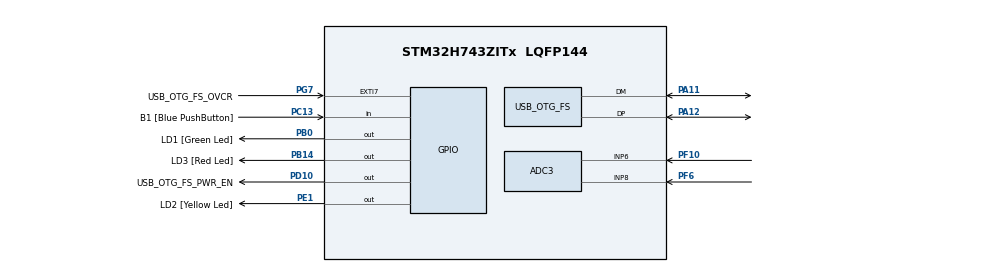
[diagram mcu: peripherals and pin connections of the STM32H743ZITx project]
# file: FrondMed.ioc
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ADC3.Channel-1\#ChannelRegularConversion=ADC_CHANNEL_6
ADC3.Channel-2\#ChannelRegularConversion=ADC_CHANNEL_8
ADC3.ExternalTrigConv=ADC_EXTERNALTRIG_T2_TRGO
ADC3.NbrOfConversion=2
ADC3.NbrOfConversionFlag=1
ADC3.OffsetNumber-1\#ChannelRegularConversion=ADC_OFFSET_NONE
ADC3.OffsetNumber-2\#ChannelRegularConversion=ADC_OFFSET_NONE
ADC3.OffsetSignedSaturation-1\#ChannelRegularConversion=DISABLE
ADC3.OffsetSignedSaturation-2\#ChannelRegularConversion=DISABLE
ADC3.Overrun=ADC_OVR_DATA_OVERWRITTEN
ADC3.Rank-1\#ChannelRegularConversion=1
ADC3.Rank-2\#ChannelRegularConversion=2
ADC3.SamplingTime-1\#ChannelRegularConversion=ADC_SAMPLETIME_1CYCLE_5
ADC3.SamplingTime-2\#ChannelRegularConversion=ADC_SAMPLETIME_1CYCLE_5
CORTEX_M7.CPU_DCache=Enabled
CORTEX_M7.CPU_ICache=Enabled
Dma.ADC3.0.Direction=DMA_PERIPH_TO_MEMORY
Dma.ADC3.0.EventEnable=DISABLE
Dma.ADC3.0.FIFOMode=DMA_FIFOMODE_DISABLE
Dma.ADC3.0.Instance=DMA1_Stream0
Dma.ADC3.0.MemDataAlignment=DMA_MDATAALIGN_HALFWORD
Dma.ADC3.0.MemInc=DMA_MINC_ENABLE
Dma.ADC3.0.Mode=DMA_CIRCULAR
Dma.ADC3.0.PeriphDataAlignment=DMA_PDATAALIGN_HALFWORD
Dma.ADC3.0.PeriphInc=DMA_PINC_DISABLE
Dma.ADC3.0.Polarity=HAL_DMAMUX_REQ_GEN_RISING
Dma.ADC3.0.Priority=DMA_PRIORITY_LOW
Dma.ADC3.0.RequestNumber=1
Dma.ADC3.0.SignalID=NONE
Dma.ADC3.0.SyncEnable=DISABLE
Dma.ADC3.0.SyncPolarity=HAL_DMAMUX_SYNC_NO_EVENT
Dma.ADC3.0.SyncRequestNumber=1
Dma.ADC3.0.SyncSignalID=NONE
Dma.Request0=ADC3
FREERTOS.INCLUDE_uxTaskPriorityGet=1
FREERTOS.INCLUDE_vTaskDelayUntil=1
FREERTOS.INCLUDE_vTaskDelete=1
FREERTOS.Tasks01=defaultTask,24,256,StartDefaultTask,Default,NULL,Dynamic,NULL,NULL
FREERTOS.configTOTAL_HEAP_SIZE=32768
Mcu.Family=STM32H7
Mcu.Name=STM32H743ZITx
Mcu.Package=LQFP144
NVIC.ADC3_IRQn=true\:5\:0\:false\:false\:true\:true\:true\:true\:true
NVIC.DMA1_Stream0_IRQn=true\:5\:0\:false\:false\:true\:true\:false\:true\:true
NVIC.OTG_FS_IRQn=true\:5\:0\:false\:false\:true\:true\:true\:true\:true
NVIC.PriorityGroup=NVIC_PRIORITYGROUP_4
NVIC.TIM6_DAC_IRQn=true\:15\:0\:false\:false\:true\:false\:false\:true\:true
NVIC.TimeBase=TIM6_DAC_IRQn
NVIC.TimeBaseIP=TIM6
PA1.Signal=ETH_REF_CLK
PA11.Mode=Device_Only
PA11.Signal=USB_OTG_FS_DM
PA12.Mode=Device_Only
PA12.Signal=USB_OTG_FS_DP
PA2.Signal=ETH_MDIO
PA7.Signal=ETH_CRS_DV
PA8.Signal=USB_OTG_FS_SOF
PA9.Signal=USB_OTG_FS_VBUS
PB0.GPIO_Label=LD1 [Green Led]
PB0.Signal=GPIO_Output
PB13.Signal=ETH_TXD1
PB14.GPIO_Label=LD3 [Red Led]
PB14.Signal=GPIO_Output
PC1.Signal=ETH_MDC
PC13.GPIO_Label=B1 [Blue PushButton]
PC13.Signal=GPIO_Input
PC14-OSC32_IN\ (OSC32_IN).Mode=LSE-External-Clock-Source
PC14-OSC32_IN\ (OSC32_IN).Signal=RCC_OSC32_IN
PC15-OSC32_OUT\ (OSC32_OUT).Signal=RCC_OSC32_OUT
PC4.Signal=ETH_RXD0
PC5.Signal=ETH_RXD1
PD10.GPIO_Label=USB_OTG_FS_PWR_EN
PD10.Signal=GPIO_Output
PD8.GPIO_Label=STLINK_RX
PD8.Signal=USART3_TX
PD9.GPIO_Label=STLINK_TX
PD9.Signal=USART3_RX
PE1.GPIO_Label=LD2 [Yellow Led]
PE1.Signal=GPIO_Output
PF10.Mode=IN6-Single-Ended
PF10.Signal=ADC3_INP6
PF6.Mode=IN8-Single-Ended
PF6.Signal=ADC3_INP8
PG11.Signal=ETH_TX_EN
PG13.Signal=ETH_TXD0
PG7.GPIO_Label=USB_OTG_FS_OVCR
PG7.Signal=GPXTI7
PH0-OSC_IN\ (PH0).Mode=HSE-External-Clock-Source
PH0-OSC_IN\ (PH0).Signal=RCC_OSC_IN
PH1-OSC_OUT\ (PH1).Signal=RCC_OSC_OUT
ProjectManager.HeapSize=0x200
ProjectManager.StackSize=0x400
ProjectManager.TargetToolchain=MDK-ARM V5.32
RCC.ADCFreq_Value=150000000
RCC.APB1Freq_Value=120000000
RCC.APB2Freq_Value=120000000
RCC.APB3Freq_Value=120000000
RCC.APB4Freq_Value=120000000
RCC.CortexFreq_Value=480000000
RCC.D1PPRE=RCC_APB3_DIV2
RCC.D2PPRE1=RCC_APB1_DIV2
RCC.D2PPRE2=RCC_APB2_DIV2
RCC.D3PPRE=RCC_APB4_DIV2
RCC.DIVM1=1
RCC.DIVM2=1
RCC.DIVN1=120
RCC.DIVN2=18
RCC.DIVP2=1
RCC.DIVQ1=15
RCC.HCLKFreq_Value=240000000
RCC.HPRE=RCC_HCLK_DIV2
RCC.HSE_VALUE=8000000
RCC.PLL2FRACN=6144
RCC.PLL3FRACN=0
RCC.PLLFRACN=0
RCC.PLLSourceVirtual=RCC_PLLSOURCE_HSE
RCC.PWR_Regulator_Voltage_Scale=PWR_REGULATOR_VOLTAGE_SCALE0
RCC.SYSCLKFreq_VALUE=480000000
RCC.SYSCLKSource=RCC_SYSCLKSOURCE_PLLCLK
RCC.USBCLockSelection=RCC_USBCLKSOURCE_HSI48
RCC.USBFreq_Value=48000000
TIM2.Period=399
TIM2.Prescaler=23
TIM2.TIM_MasterOutputTrigger=TIM_TRGO_UPDATE
USB_DEVICE.CLASS_NAME_FS=CDC
USB_DEVICE.VirtualMode-CDC_FS=Cdc
USB_DEVICE.VirtualModeFS=Cdc_FS
USB_OTG_FS.VirtualMode=Device_Only
USB_OTG_FS.dma_enable=ENABLE
VP_FREERTOS_VS_CMSIS_V2.Mode=CMSIS_V2
VP_SYS_VS_tim6.Mode=TIM6
VP_TIM2_VS_ClockSourceINT.Mode=Internal
VP_USB_DEVICE_VS_USB_DEVICE_CDC_FS.Mode=CDC_FS
board=NUCLEO-H743ZI2

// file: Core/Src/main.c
/* USER CODE BEGIN Header */
/**
  ******************************************************************************
  * @file           : main.c
  * @brief          : Main program body
  ******************************************************************************
  * @attention
  *
  * Copyright (c) 2022 STMicroelectronics.
  * All rights reserved.
  *
  * This software is licensed under terms that can be found in the LICENSE file
  * in the root directory of this software component.
  * If no LICENSE file comes with this software, it is provided AS-IS.
  *
  ******************************************************************************
  */
/* USER CODE END Header */
#include "main.h"
#include "cmsis_os.h"
#include "usb_device.h"

/* USER CODE BEGIN PM */
extern  void mainThread(void* arg);

/* USER CODE END PM */

ADC_HandleTypeDef hadc3;
DMA_HandleTypeDef hdma_adc3;

TIM_HandleTypeDef htim2;

/* Definitions for defaultTask */
osThreadId_t defaultTaskHandle;
const osThreadAttr_t defaultTask_attributes = {
  .name = "defaultTask",
  .stack_size = 256 * 4,
  .priority = (osPriority_t) osPriorityNormal,
};

void SystemClock_Config(void);
static void MX_GPIO_Init(void);
static void MX_ADC3_Init(void);
static void MX_DMA_Init(void);
static void MX_TIM2_Init(void);
void StartDefaultTask(void *argument);

int main(void)
{

  /* Enable I-Cache---------------------------------------------------------*/
  SCB_EnableICache();

  /* Enable D-Cache---------------------------------------------------------*/
  SCB_EnableDCache();

  /* MCU Configuration--------------------------------------------------------*/

  /* Reset of all peripherals, Initializes the Flash interface and the Systick. */
  HAL_Init();

  /* Configure the system clock */
  SystemClock_Config();

  /* Initialize all configured peripherals */
  MX_GPIO_Init();
  MX_ADC3_Init();
  MX_DMA_Init();
  MX_TIM2_Init();

  /* Init scheduler */
  osKernelInitialize();

  /* Create the thread(s) */
  /* creation of defaultTask */
  defaultTaskHandle = osThreadNew(mainThread, NULL, &defaultTask_attributes);

  /* Start scheduler */
  osKernelStart();

  /* We should never get here as control is now taken by the scheduler */
  /* Infinite loop */
  while (1)
  {

  }
}

void SystemClock_Config(void)
{
  RCC_OscInitTypeDef RCC_OscInitStruct = {0};
  RCC_ClkInitTypeDef RCC_ClkInitStruct = {0};

  /** Supply configuration update enable
  */
  HAL_PWREx_ConfigSupply(PWR_LDO_SUPPLY);

  /** Configure the main internal regulator output voltage
  */
  __HAL_PWR_VOLTAGESCALING_CONFIG(PWR_REGULATOR_VOLTAGE_SCALE1);

  while(!__HAL_PWR_GET_FLAG(PWR_FLAG_VOSRDY)) {}

  __HAL_RCC_SYSCFG_CLK_ENABLE();
  __HAL_PWR_VOLTAGESCALING_CONFIG(PWR_REGULATOR_VOLTAGE_SCALE0);

  while(!__HAL_PWR_GET_FLAG(PWR_FLAG_VOSRDY)) {}

  /** Macro to configure the PLL clock source
  */
  __HAL_RCC_PLL_PLLSOURCE_CONFIG(RCC_PLLSOURCE_HSE);

  /** Initializes the RCC Oscillators according to the specified parameters
  * in the RCC_OscInitTypeDef structure.
  */
  RCC_OscInitStruct.OscillatorType = RCC_OSCILLATORTYPE_HSI48|RCC_OSCILLATORTYPE_HSE;
  RCC_OscInitStruct.HSEState = RCC_HSE_BYPASS;
  RCC_OscInitStruct.HSI48State = RCC_HSI48_ON;
  RCC_OscInitStruct.PLL.PLLState = RCC_PLL_ON;
  RCC_OscInitStruct.PLL.PLLSource = RCC_PLLSOURCE_HSE;
  RCC_OscInitStruct.PLL.PLLM = 1;
  RCC_OscInitStruct.PLL.PLLN = 120;
  RCC_OscInitStruct.PLL.PLLP = 2;
  RCC_OscInitStruct.PLL.PLLQ = 15;
  RCC_OscInitStruct.PLL.PLLR = 2;
  RCC_OscInitStruct.PLL.PLLRGE = RCC_PLL1VCIRANGE_3;
  RCC_OscInitStruct.PLL.PLLVCOSEL = RCC_PLL1VCOWIDE;
  RCC_OscInitStruct.PLL.PLLFRACN = 0;
  if (HAL_RCC_OscConfig(&RCC_OscInitStruct) != HAL_OK)
  {
    Error_Handler();
  }

  /** Initializes the CPU, AHB and APB buses clocks
  */
  RCC_ClkInitStruct.ClockType = RCC_CLOCKTYPE_HCLK|RCC_CLOCKTYPE_SYSCLK
                              |RCC_CLOCKTYPE_PCLK1|RCC_CLOCKTYPE_PCLK2
                              |RCC_CLOCKTYPE_D3PCLK1|RCC_CLOCKTYPE_D1PCLK1;
  RCC_ClkInitStruct.SYSCLKSource = RCC_SYSCLKSOURCE_PLLCLK;
  RCC_ClkInitStruct.SYSCLKDivider = RCC_SYSCLK_DIV1;
  RCC_ClkInitStruct.AHBCLKDivider = RCC_HCLK_DIV2;
  RCC_ClkInitStruct.APB3CLKDivider = RCC_APB3_DIV2;
  RCC_ClkInitStruct.APB1CLKDivider = RCC_APB1_DIV2;
  RCC_ClkInitStruct.APB2CLKDivider = RCC_APB2_DIV2;
  RCC_ClkInitStruct.APB4CLKDivider = RCC_APB4_DIV2;

  if (HAL_RCC_ClockConfig(&RCC_ClkInitStruct, FLASH_LATENCY_4) != HAL_OK)
  {
    Error_Handler();
  }
}

static void MX_ADC3_Init(void)
{

  ADC_ChannelConfTypeDef sConfig = {0};

  /** Common config
  */
  hadc3.Instance = ADC3;
  hadc3.Init.Resolution = ADC_RESOLUTION_16B;
  hadc3.Init.ScanConvMode = ADC_SCAN_ENABLE;
  hadc3.Init.EOCSelection = ADC_EOC_SINGLE_CONV;
  hadc3.Init.LowPowerAutoWait = DISABLE;
  hadc3.Init.ContinuousConvMode = DISABLE;
  hadc3.Init.NbrOfConversion = 2;
  hadc3.Init.DiscontinuousConvMode = DISABLE;
  hadc3.Init.ExternalTrigConv = ADC_EXTERNALTRIG_T2_TRGO;
  hadc3.Init.ExternalTrigConvEdge = ADC_EXTERNALTRIGCONVEDGE_RISING;
  hadc3.Init.ConversionDataManagement = ADC_CONVERSIONDATA_DR;
  hadc3.Init.Overrun = ADC_OVR_DATA_OVERWRITTEN;
  hadc3.Init.LeftBitShift = ADC_LEFTBITSHIFT_NONE;
  hadc3.Init.OversamplingMode = DISABLE;
  if (HAL_ADC_Init(&hadc3) != HAL_OK)
  {
    Error_Handler();
  }

  /** Configure Regular Channel
  */
  sConfig.Channel = ADC_CHANNEL_6;
  sConfig.Rank = ADC_REGULAR_RANK_1;
  sConfig.SamplingTime = ADC_SAMPLETIME_1CYCLE_5;
  sConfig.SingleDiff = ADC_SINGLE_ENDED;
  sConfig.OffsetNumber = ADC_OFFSET_NONE;
  sConfig.Offset = 0;
  sConfig.OffsetSignedSaturation = DISABLE;
  if (HAL_ADC_ConfigChannel(&hadc3, &sConfig) != HAL_OK)
  {
    Error_Handler();
  }

  /** Configure Regular Channel
  */
  sConfig.Channel = ADC_CHANNEL_8;
  sConfig.Rank = ADC_REGULAR_RANK_2;
  if (HAL_ADC_ConfigChannel(&hadc3, &sConfig) != HAL_OK)
  {
    Error_Handler();
  }

}

static void MX_TIM2_Init(void)
{

  TIM_ClockConfigTypeDef sClockSourceConfig = {0};
  TIM_MasterConfigTypeDef sMasterConfig = {0};

  htim2.Instance = TIM2;
  htim2.Init.Prescaler = 23;
  htim2.Init.CounterMode = TIM_COUNTERMODE_UP;
  htim2.Init.Period = 199;
  htim2.Init.ClockDivision = TIM_CLOCKDIVISION_DIV1;
  htim2.Init.AutoReloadPreload = TIM_AUTORELOAD_PRELOAD_DISABLE;
  if (HAL_TIM_Base_Init(&htim2) != HAL_OK)
  {
    Error_Handler();
  }
  sClockSourceConfig.ClockSource = TIM_CLOCKSOURCE_INTERNAL;
  if (HAL_TIM_ConfigClockSource(&htim2, &sClockSourceConfig) != HAL_OK)
  {
    Error_Handler();
  }
  sMasterConfig.MasterOutputTrigger = TIM_TRGO_UPDATE;
  sMasterConfig.MasterSlaveMode = TIM_MASTERSLAVEMODE_DISABLE;
  if (HAL_TIMEx_MasterConfigSynchronization(&htim2, &sMasterConfig) != HAL_OK)
  {
    Error_Handler();
  }

}

static void MX_DMA_Init(void)
{

  /* DMA controller clock enable */
  __HAL_RCC_DMA1_CLK_ENABLE();

  /* DMA interrupt init */
  /* DMA1_Stream0_IRQn interrupt configuration */
  HAL_NVIC_SetPriority(DMA1_Stream0_IRQn, 5, 0);
  HAL_NVIC_EnableIRQ(DMA1_Stream0_IRQn);

}

static void MX_GPIO_Init(void)
{
  GPIO_InitTypeDef GPIO_InitStruct = {0};

  /* GPIO Ports Clock Enable */
  __HAL_RCC_GPIOC_CLK_ENABLE();
  __HAL_RCC_GPIOF_CLK_ENABLE();
  __HAL_RCC_GPIOH_CLK_ENABLE();
  __HAL_RCC_GPIOA_CLK_ENABLE();
  __HAL_RCC_GPIOB_CLK_ENABLE();
  __HAL_RCC_GPIOD_CLK_ENABLE();
  __HAL_RCC_GPIOG_CLK_ENABLE();
  __HAL_RCC_GPIOE_CLK_ENABLE();

  /*Configure GPIO pin Output Level */
  HAL_GPIO_WritePin(GPIOB, LD1_Pin|LD3_Pin, GPIO_PIN_RESET);

  /*Configure GPIO pin Output Level */
  HAL_GPIO_WritePin(USB_OTG_FS_PWR_EN_GPIO_Port, USB_OTG_FS_PWR_EN_Pin, GPIO_PIN_RESET);

  /*Configure GPIO pin Output Level */
  HAL_GPIO_WritePin(LD2_GPIO_Port, LD2_Pin, GPIO_PIN_RESET);

  /*Configure GPIO pin : B1_Pin */
  GPIO_InitStruct.Pin = B1_Pin;
  GPIO_InitStruct.Mode = GPIO_MODE_INPUT;
  GPIO_InitStruct.Pull = GPIO_NOPULL;
  HAL_GPIO_Init(B1_GPIO_Port, &GPIO_InitStruct);

  /*Configure GPIO pins : PC1 PC4 PC5 */
  GPIO_InitStruct.Pin = GPIO_PIN_1|GPIO_PIN_4|GPIO_PIN_5;
  GPIO_InitStruct.Mode = GPIO_MODE_AF_PP;
  GPIO_InitStruct.Pull = GPIO_NOPULL;
  GPIO_InitStruct.Speed = GPIO_SPEED_FREQ_LOW;
  GPIO_InitStruct.Alternate = GPIO_AF11_ETH;
  HAL_GPIO_Init(GPIOC, &GPIO_InitStruct);

  /*Configure GPIO pins : PA1 PA2 PA7 */
  GPIO_InitStruct.Pin = GPIO_PIN_1|GPIO_PIN_2|GPIO_PIN_7;
  GPIO_InitStruct.Mode = GPIO_MODE_AF_PP;
  GPIO_InitStruct.Pull = GPIO_NOPULL;
  GPIO_InitStruct.Speed = GPIO_SPEED_FREQ_LOW;
  GPIO_InitStruct.Alternate = GPIO_AF11_ETH;
  HAL_GPIO_Init(GPIOA, &GPIO_InitStruct);

  /*Configure GPIO pins : LD1_Pin LD3_Pin */
  GPIO_InitStruct.Pin = LD1_Pin|LD3_Pin;
  GPIO_InitStruct.Mode = GPIO_MODE_OUTPUT_PP;
  GPIO_InitStruct.Pull = GPIO_NOPULL;
  GPIO_InitStruct.Speed = GPIO_SPEED_FREQ_LOW;
  HAL_GPIO_Init(GPIOB, &GPIO_InitStruct);

  /*Configure GPIO pin : PB13 */
  GPIO_InitStruct.Pin = GPIO_PIN_13;
  GPIO_InitStruct.Mode = GPIO_MODE_AF_PP;
  GPIO_InitStruct.Pull = GPIO_NOPULL;
  GPIO_InitStruct.Speed = GPIO_SPEED_FREQ_LOW;
  GPIO_InitStruct.Alternate = GPIO_AF11_ETH;
  HAL_GPIO_Init(GPIOB, &GPIO_InitStruct);

  /*Configure GPIO pins : STLINK_RX_Pin STLINK_TX_Pin */
  GPIO_InitStruct.Pin = STLINK_RX_Pin|STLINK_TX_Pin;
  GPIO_InitStruct.Mode = GPIO_MODE_AF_PP;
  GPIO_InitStruct.Pull = GPIO_NOPULL;
  GPIO_InitStruct.Speed = GPIO_SPEED_FREQ_LOW;
  GPIO_InitStruct.Alternate = GPIO_AF7_USART3;
  HAL_GPIO_Init(GPIOD, &GPIO_InitStruct);

  /*Configure GPIO pin : USB_OTG_FS_PWR_EN_Pin */
  GPIO_InitStruct.Pin = USB_OTG_FS_PWR_EN_Pin;
  GPIO_InitStruct.Mode = GPIO_MODE_OUTPUT_PP;
  GPIO_InitStruct.Pull = GPIO_NOPULL;
  GPIO_InitStruct.Speed = GPIO_SPEED_FREQ_LOW;
  HAL_GPIO_Init(USB_OTG_FS_PWR_EN_GPIO_Port, &GPIO_InitStruct);

  /*Configure GPIO pin : USB_OTG_FS_OVCR_Pin */
  GPIO_InitStruct.Pin = USB_OTG_FS_OVCR_Pin;
  GPIO_InitStruct.Mode = GPIO_MODE_IT_RISING;
  GPIO_InitStruct.Pull = GPIO_NOPULL;
  HAL_GPIO_Init(USB_OTG_FS_OVCR_GPIO_Port, &GPIO_InitStruct);

  /*Configure GPIO pins : PG11 PG13 */
  GPIO_InitStruct.Pin = GPIO_PIN_11|GPIO_PIN_13;
  GPIO_InitStruct.Mode = GPIO_MODE_AF_PP;
  GPIO_InitStruct.Pull = GPIO_NOPULL;
  GPIO_InitStruct.Speed = GPIO_SPEED_FREQ_LOW;
  GPIO_InitStruct.Alternate = GPIO_AF11_ETH;
  HAL_GPIO_Init(GPIOG, &GPIO_InitStruct);

  /*Configure GPIO pin : LD2_Pin */
  GPIO_InitStruct.Pin = LD2_Pin;
  GPIO_InitStruct.Mode = GPIO_MODE_OUTPUT_PP;
  GPIO_InitStruct.Pull = GPIO_NOPULL;
  GPIO_InitStruct.Speed = GPIO_SPEED_FREQ_LOW;
  HAL_GPIO_Init(LD2_GPIO_Port, &GPIO_InitStruct);

}

void StartDefaultTask(void *argument)
{
  /* init code for USB_DEVICE */
  MX_USB_DEVICE_Init();
  for(;;)
  {
    osDelay(1);
  }
}

void HAL_TIM_PeriodElapsedCallback(TIM_HandleTypeDef *htim)
{
  if (htim->Instance == TIM6) {
    HAL_IncTick();
  }
}

void Error_Handler(void)
{
  __disable_irq();
  while (1)
  {
  }
}
